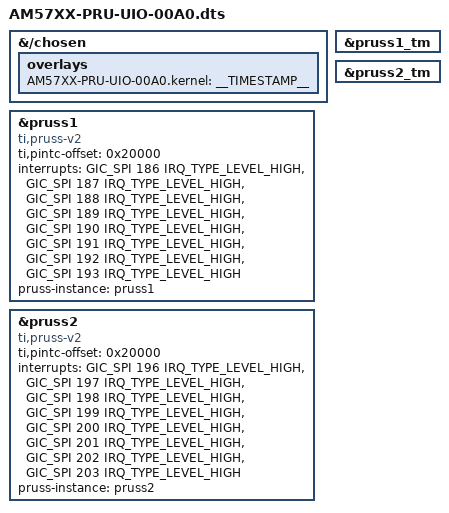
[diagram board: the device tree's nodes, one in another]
// SPDX-License-Identifier: GPL-2.0-only
/*
 * Copyright (C) 2012 Texas Instruments Incorporated - https://www.ti.com/
 */

/dts-v1/;
/plugin/;

#include <dt-bindings/interrupt-controller/arm-gic.h>
#include <dt-bindings/interrupt-controller/irq.h>

/*
 * Helper to show loaded overlays under: /proc/device-tree/chosen/overlays/
 */
&{/chosen} {
	overlays {
		AM57XX-PRU-UIO-00A0.kernel = __TIMESTAMP__;
	};
};

&pruss1_tm {
	status = "okay";
};

&pruss1 {
	compatible = "ti,pruss-v2";
	ti,pintc-offset = <0x20000>;
	interrupts = <GIC_SPI 186 IRQ_TYPE_LEVEL_HIGH>,
		     <GIC_SPI 187 IRQ_TYPE_LEVEL_HIGH>,
		     <GIC_SPI 188 IRQ_TYPE_LEVEL_HIGH>,
		     <GIC_SPI 189 IRQ_TYPE_LEVEL_HIGH>,
		     <GIC_SPI 190 IRQ_TYPE_LEVEL_HIGH>,
		     <GIC_SPI 191 IRQ_TYPE_LEVEL_HIGH>,
		     <GIC_SPI 192 IRQ_TYPE_LEVEL_HIGH>,
		     <GIC_SPI 193 IRQ_TYPE_LEVEL_HIGH>;
	pruss-instance = "pruss1";
};

&pruss2_tm {
	status = "okay";
};

&pruss2 {
	compatible = "ti,pruss-v2";
	ti,pintc-offset = <0x20000>;
	interrupts = <GIC_SPI 196 IRQ_TYPE_LEVEL_HIGH>,
		     <GIC_SPI 197 IRQ_TYPE_LEVEL_HIGH>,
		     <GIC_SPI 198 IRQ_TYPE_LEVEL_HIGH>,
		     <GIC_SPI 199 IRQ_TYPE_LEVEL_HIGH>,
		     <GIC_SPI 200 IRQ_TYPE_LEVEL_HIGH>,
		     <GIC_SPI 201 IRQ_TYPE_LEVEL_HIGH>,
		     <GIC_SPI 202 IRQ_TYPE_LEVEL_HIGH>,
		     <GIC_SPI 203 IRQ_TYPE_LEVEL_HIGH>;
	pruss-instance = "pruss2";
};
